# DEBUGSS_DEBUGSS_ARM_CTI_6_CFG_CSCTI_CFG_00073C02D000h register map
Vendor: Texas Instruments
Peripheral module from a debugger description file (folder am62L).
Registers are 32-bit, read-write, reset values left out (the file's numbers can be read two ways) unless marked. A register's access mark holds for its fields unless they carry their own. Offsets are as the file gives them; lines under a group give offsets from that group; [hi:lo] are bit positions; {n}, {i} and the like mark numbered series; 'fields as' and 'values as' point back to an identical list; <NAME> marks a mode.

## DEBUGSS_ARM_CTI_6_CFG_CSCTI_CFG
0x00 DEBUGSS_ARM_CTI_6_CFG_CSCTI_CFG_CTICONTROL — The CTI Control Register enables the CTI. >
  [0] GLBEN — Enables or disables the ECT.
0x10 DEBUGSS_ARM_CTI_6_CFG_CSCTI_CFG_CTIINTACK — The CTI Interrupt Acknowledge Register is write-only. Any bits written as a 1 cause the ctitrigout output signal to be acknowledged. The acknowledgement is cleared when MAPTRIGOUT is deactivated. This register is used when the ctitrigout is used as a sticky output, that is, no hardware acknowledge is supplied, and a software acknowledge is required.
  [7:0] INTACK — Acknowledges the corresponding ctitrigout output. There is one bit of the register for each ctitrigout output. When a 1 is written to a bit in this register, the corresponding ctitrigout is acknowledged and is cleared when MAPTRIGOUT is LOW. Writing a 0 to any of the bits in this register has no effect.
0x14 DEBUGSS_ARM_CTI_6_CFG_CSCTI_CFG_CTIAPPSET — The CTI Application Trigger Set Register is read/write. A write to this register causes a channel event to be raised, corresponding to the bit written to.
  [3:0] APPSET — Setting a bit HIGH generates a channel event for the selected channel. There is one bit of the register for each channel. Read : 0 = application trigger inactive (reset). 1 = application trigger active. Write : 0 = no effect. 1 = generate channel event.
0x18 DEBUGSS_ARM_CTI_6_CFG_CSCTI_CFG_CTIAPPCLEAR — The CTI Interrupt Acknowledge Register is write-only. A write to this register causes a channel event to be cleared, corresponding to the bit written to.
  [3:0] APPCLEAR — Clears corresponding bits in the CTIAPPSET register. There is one bit of the register for each channel. When a 1 is written to a bit in this register, the corresponding application trigger is disabled in the CTIAPPSET register. Writing a 0 to any of the bits in this register has no effect.
0x1C DEBUGSS_ARM_CTI_6_CFG_CSCTI_CFG_CTIAPPPULSE — The CTI Application Pulse Register is write-only. A write to this register causes a channel event pulse, one cticlk period, to be generated, corresponding to the bit written to. The pulse external to the ECT can be extended to multi-cycle by the handshaking interface circuits. This register clears itself immediately, so it can be repeatedly written to without software having to clear it.
  [3:0] APPULSE — Setting a bit HIGH generates a channel event pulse for the selected channel. There is one bit of the register for each channel. When a 1 is written to a bit in this register, a corresponding channel event pulse is generated for one cticlk period. Writing a 0 to any of the bits in this register has no effect.
0x20 DEBUGSS_ARM_CTI_6_CFG_CSCTI_CFG_CTIINEN0 — The CTI Trigger 0 to Channel Enable Register enables the signalling of an event on CTM channels when the core issues a trigger, ctitrigin, to the CTI. Within this register there is one bit for each of the four channels implemented. This register does not affect the application trigger operations.
  [3:0] TRIGINEN — Enables a cross trigger event to the corresponding channel when an ctitrigin is activated. There is one bit of the field for each of the four channels. When a 1 is written to a bit in this register, it enables the ctitrigin signal to generate an event on the respective channel of the CTM. For example, TRIGINEN[0] set to 1 enables ctitrigin onto channel 0. Writing a 0 to any of the bits in this register disables the ctitrigin signal from generating an event on the respective channel of the CTM. Reading this register returns the programmed value.
0x24 DEBUGSS_ARM_CTI_6_CFG_CSCTI_CFG_CTIINEN1 — The CTI Trigger 1 to Channel Enable Register enables the signalling of an event on CTM channels when the core issues a trigger, ctitrigin, to the CTI. Within this register there is one bit for each of the four channels implemented. This register does not affect the application trigger operations.
  fields as DEBUGSS_ARM_CTI_6_CFG_CSCTI_CFG_CTIINEN0
{0x20+4i} DEBUGSS_ARM_CTI_6_CFG_CSCTI_CFG_CTIINEN{i} (i=2..7) — The CTI Trigger to Channel Enable Register 0 enables the signalling of an event on CTM channels when the core issues a trigger, ctitrigin, to the CTI. Within this register there is one bit for each of the four channels implemented. This register does not affect the application trigger operations.
  fields as DEBUGSS_ARM_CTI_6_CFG_CSCTI_CFG_CTIINEN0
0xA0 DEBUGSS_ARM_CTI_6_CFG_CSCTI_CFG_CTIOUTEN0 — The CTI Channel to Trigger 0 Enable Registers define which channels can generate a ctitrigout[0] output. Within this register there is one bit for each of the four channels implemented. This register affects the mapping from application trigger to trigger outputs.
  [3:0] TRIGOUTEN — Changing the value of this bit from a 0 to a 1 enables a channel event for the corresponding channel to generate a ctitrigout[1] output. There is one bit of the field for each of the four channels. When a 1 is written to a bit in this register, the channel input (ctichin) from the CTM is routed to the ctitrigout output. For example, enabling bit 0 enables ctichin[0] to cause a trigger event on the ctitrigout[0] output. When a 0 is written to any of the bits in this register, the channel input (ctichin) from the CTM is not routed to the ctitrigout output. Reading this register returns the programmed value.
{0xA0+4i} DEBUGSS_ARM_CTI_6_CFG_CSCTI_CFG_CTIOUTEN{i} (i=1..7) — The CTI Channel to Trigger {i} Enable Registers define which channels can generate a ctitrigout[{i}] output. Within this register there is one bit for each of the four channels implemented. This register affects the mapping from application trigger to trigger outputs.
  [3:0] TRIGOUTEN — Changing the value of this bit from a 0 to a 1 enables a channel event for the corresponding channel to generate a ctitrigout[{i}] output. There is one bit of the field for each of the four channels. When a 1 is written to a bit in this register, the channel input (ctichin) from the CTM is routed to the ctitrigout output. For example, enabling bit 0 enables ctichin[0] to cause a trigger event on the ctitrigout[{i}] output. When a 0 is written to any of the bits in this register, the channel input (ctichin) from the CTM is not routed to the ctitrigout output. Reading this register returns the programmed value.
0x130 DEBUGSS_ARM_CTI_6_CFG_CSCTI_CFG_CTITRIGINSTATUS ro — The CTI Trigger In Status Register provides the status of the ctitrigin inputs.
  [7:0] TRIGINSTATUS — Shows the status of the ctitrigin inputs. 1 = ctitrigin is active. 0 = ctitrigin is inactive. Because the register provides a view of the raw ctitrigin inputs, the reset value is unknown. There is one bit of the field for each trigger input.
0x134 DEBUGSS_ARM_CTI_6_CFG_CSCTI_CFG_CTITRIGOUTSTATUS ro — The CTI Trigger Out Status Register provides the status of the ctitrigout outputs.
  [7:0] TRIGOUTSTATUS — Shows the status of the ctitrigout outputs. 1 = ctitrigout is active. 0 = ctitrigout is inactive. There is one bit of the field for each trigger output.
0x138 DEBUGSS_ARM_CTI_6_CFG_CSCTI_CFG_CTICHINSTATUS ro — The CTI Channel In Status Register provides the status of the ctichin inputs.
  [3:0] CTICHINSTATUS — Shows the status of the ctichin inputs. 1 = ctichin is active. 0 = ctichin is inactive. Because the register provides a view of the raw ctichin inputs, the reset value is unknown. There is one bit of the field for each channel input.
0x13C DEBUGSS_ARM_CTI_6_CFG_CSCTI_CFG_CTICHOUTSTATUS ro — The CTI Channel Out Status Register provides the status of the CTI ctichout outputs.
  [3:0] CTICHOUTSTATUS — Shows the status of the ctichout outputs. 1 = ctichout is active. 0 = ctichout is inactive. There is one bit of the field for each channel output.
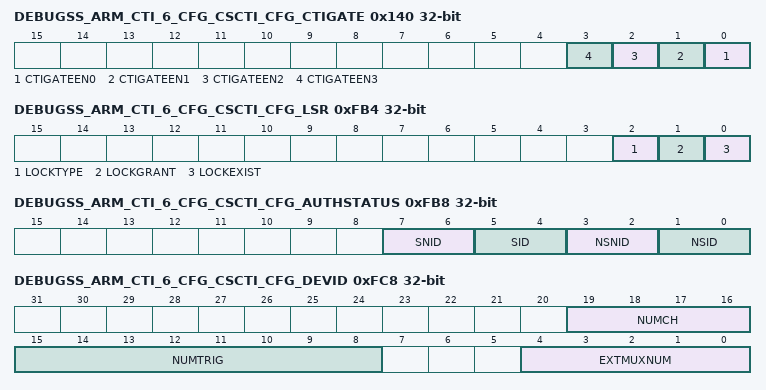
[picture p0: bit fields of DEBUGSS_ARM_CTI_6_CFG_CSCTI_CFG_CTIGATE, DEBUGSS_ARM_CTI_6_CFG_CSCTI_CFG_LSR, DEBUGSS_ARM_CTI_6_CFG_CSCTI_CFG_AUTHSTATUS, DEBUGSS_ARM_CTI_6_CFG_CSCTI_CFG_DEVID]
0x140 DEBUGSS_ARM_CTI_6_CFG_CSCTI_CFG_CTIGATE — The Gate Enable Register prevents the channels from propagating through the CTM to other CTIs. This enables local cross-triggering, for example for causing an interrupt when the ETM trigger occurs. It can be used effectively with CTIAPPSET, CTIAPPCLEAR, and CTIAPPPULSE for asserting trigger outputs by asserting channels, without affecting the rest of the system. On reset, this register is 0xF, and channel propagation is enabled.
  [n] CTIGATEEN{n} (n=0..3) — Enable CTICHOUT{n}. Set to 0 to disable channel propagation.
0x144 DEBUGSS_ARM_CTI_6_CFG_CSCTI_CFG_ASICCTL — Implementation-defined ASIC control, value written to the register is output on asicctl[7 : 0].
  [7:0] ASICCTL — Implementation-defined ASIC control, value written to the register is output on asicctl[7 : 0]. If external multiplexing of trigger signals is implemented then the number of multiplexed signals on each trigger must be reflected within the Device ID Register. This is done within a Verilog define EXTMUXNUM.
0xEDC DEBUGSS_ARM_CTI_6_CFG_CSCTI_CFG_ITCHINACK — This register is a write-only register. It can be used to set the value of the CTCHINACK outputs.
  [3:0] CTCHINACK — Set the value of the CTCHINACK outputs.
0xEE0 DEBUGSS_ARM_CTI_6_CFG_CSCTI_CFG_ITTRIGINACK — This register is a write-only register. It can be used to set the value of the CTTRIGINACK outputs.
  [7:0] CTTRIGINACK — Set the value of the CTTRIGINACK outputs.
0xEE4 DEBUGSS_ARM_CTI_6_CFG_CSCTI_CFG_ITCHOUT — This register is a write-only register. It can be used to set the value of the CTCHOUT outputs.
  [3:0] CTCHOUT — Set the value of the CTCHOUT outputs.
0xEE8 DEBUGSS_ARM_CTI_6_CFG_CSCTI_CFG_ITTRIGOUT — This register is a write-only register. It can be used to set the value of the CTTRIGOUT outputs.
  [7:0] CTTRIGOUT — Set the value of the CTTRIGOUT outputs.
0xEEC DEBUGSS_ARM_CTI_6_CFG_CSCTI_CFG_ITCHOUTACK ro — This register is a read-only register. It can be used to read the values of the CTCHOUTACK inputs.
  [3:0] CTCHOUTACK — Read the values of the CTCHOUTACK inputs.
0xEF0 DEBUGSS_ARM_CTI_6_CFG_CSCTI_CFG_ITTRIGOUTACK ro — This register is a read-only register. It can be used to read the values of the CTTRIGOUTACK inputs.
  [7:0] CTTRIGOUTACK — Read the value of the CTTRIGOUTACK inputs.
0xEF4 DEBUGSS_ARM_CTI_6_CFG_CSCTI_CFG_ITCHIN ro — This register is a read-only register. It can be used to read the values of the CTCHIN inputs.
  [3:0] CTCHIN — Read the value of the CTCHIN inputs.
0xEF8 DEBUGSS_ARM_CTI_6_CFG_CSCTI_CFG_ITTRIGIN ro — This register is a read-only register. It can be used to read the values of the CTTRIGIN inputs.
  [7:0] CTTRIGIN — Read the values of the CTTRIGIN inputs.
0xF00 DEBUGSS_ARM_CTI_6_CFG_CSCTI_CFG_ITCTRL — This register is used to enable topology detection. For more information see the CoreSight Architecture Specification. This register enables the component to switch from a functional mode, the default behavior, to integration mode where the inputs and outputs of the component can be directly controlled for the purpose of integration testing and topology solving. Note : When a device has been in integration mode, it might not function with the original behavior. After performing integration or topology detection, you must reset the system to ensure correct behavior of CoreSight and other connected system components that are affected by the integration or topology detection.
  [0] INTEGRATION_MODE — Allows the component to switch from functional mode to integration mode or back.
0xFA0 DEBUGSS_ARM_CTI_6_CFG_CSCTI_CFG_CLAIMSET — This is used in conjunction with Claim Tag Clear Register, CLAIMCLR. This register forms one half of the Claim Tag value. This location allows individual bits to be set, write, and returns the number of bits that can be set, read.
  [3:0] CLAIMSET — This claim tag bit is implemented
0xFA4 DEBUGSS_ARM_CTI_6_CFG_CSCTI_CFG_CLAIMCLR — This register is used in conjunction with Claim Tag Set Register, CLAIMSET. This register forms one half of the Claim Tag value. This location enables individual bits to be cleared, write, and returns the current Claim Tag value, read.
  [3:0] CLAIMCLR — The value present reflects the current setting of the Claim Tag.
0xFB0 DEBUGSS_ARM_CTI_6_CFG_CSCTI_CFG_LAR — This is used to enable write access to device registers. External accesses from a debugger (paddrdbg31 = 1) are not subject to the Lock Registers. A debugger does not have to unlock the component in order to write and modify the registers in the component.
  [31:0] ACCESS_W — A write of 0xC5ACCE55 enables further write access to this device. A write of any value other than 0xC5ACCE55 will have the affect of removing write access.
0xFB4 DEBUGSS_ARM_CTI_6_CFG_CSCTI_CFG_LSR ro — This indicates the status of the Lock control mechanism. This lock prevents accidental writes by code under debug. When locked, write access is blocked to all registers, except the Lock Access Register. External accesses from a debugger (paddrdbg31 = 1) are not subject to the Lock Registers. This register reads as 0 when read from an external debugger (paddrdbg31 = 1).
  [2] LOCKTYPE — Indicates if the Lock Access Register (0xFB0) is implemented as 8-bit or 32-bit
  [1] LOCKGRANT — Returns the current status of the Lock. This bit reads as 0 when read from an external debugger (paddrdbg31 = 1) since external debugger accesses are not subject to Lock Registers.
  [0] LOCKEXIST — Indicates that a lock control mechanism exists for this device. This bit reads as 0 when read from an external debugger (paddrdbg31 = 1) since external debugger accesses are not subject to Lock Registers.
0xFB8 DEBUGSS_ARM_CTI_6_CFG_CSCTI_CFG_AUTHSTATUS ro — Reports what functionality is currently permitted by the authentication interface.
  [7:6] SNID — Indicates the security level for secure non-invasive debug
  [5:4] SID — Indicates the security level for secure invasive debug
  [3:2] NSNID — Indicates the security level for non-secure non-invasive debug
  [1:0] NSID — Indicates the security level for non-secure invasive debug
0xFC8 DEBUGSS_ARM_CTI_6_CFG_CSCTI_CFG_DEVID ro — This register indicates the capabilities of the CTI.
  [19:16] NUMCH — Number of ECT channels available.
  [15:8] NUMTRIG — Number of ECT triggers available.
  [4:0] EXTMUXNUM — Indicates the number of multiplexing available on Trigger Inputs and Trigger Outputs using asicctl. Default value of 5'b00000 indicating no multiplexing present. Reflects the value of the Verilog define EXTMUXNUM that the user must alter accordingly.
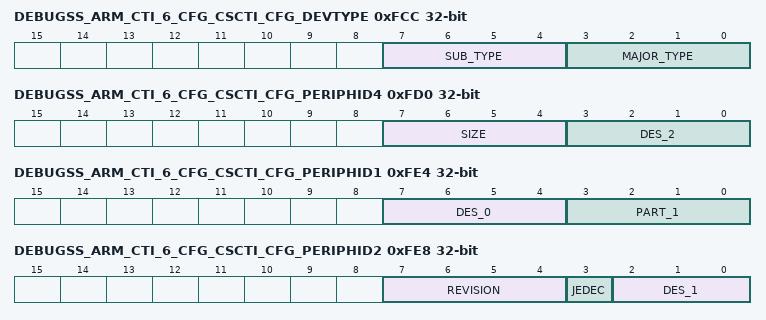
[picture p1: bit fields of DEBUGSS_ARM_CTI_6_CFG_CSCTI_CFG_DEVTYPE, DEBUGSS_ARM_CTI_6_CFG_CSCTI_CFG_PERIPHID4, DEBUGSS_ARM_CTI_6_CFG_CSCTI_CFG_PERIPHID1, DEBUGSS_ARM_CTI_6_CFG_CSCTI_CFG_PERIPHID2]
0xFCC DEBUGSS_ARM_CTI_6_CFG_CSCTI_CFG_DEVTYPE ro — It provides a debugger with information about the component when the Part Number field is not recognized. The debugger can then report this information.
  [7:4] SUB_TYPE — Sub-classification within the major category
  [3:0] MAJOR_TYPE — Major classification grouping for this debug/trace component
0xFD0 DEBUGSS_ARM_CTI_6_CFG_CSCTI_CFG_PERIPHID4 ro — Part of the set of Peripheral Identification registers. Contains part of the designer identity and the memory footprint indicator.
  [7:4] SIZE — This is a 4-bit value that indicates the total contiguous size of the memory window used by this component in powers of 2 from the standard 4KB. If a component only requires the standard 4KB then this should read as 0x0, 4KB only, for 8KB set to 0x1, 16KB == 0x2, 32KB == 0x3, and so on.
  [3:0] DES_2 — JEDEC continuation code indicating the designer of the component (along with the identity code)
0xFE0 DEBUGSS_ARM_CTI_6_CFG_CSCTI_CFG_PERIPHID0 ro — Part of the set of Peripheral Identification registers. Contains part of the designer specific part number.
  [7:0] PART_0 — Bits [7 : 0] of the component's part number. This is selected by the designer of the component.
0xFE4 DEBUGSS_ARM_CTI_6_CFG_CSCTI_CFG_PERIPHID1 ro — Part of the set of Peripheral Identification registers. Contains part of the designer specific part number and part of the designer identity.
  [7:4] DES_0 — Bits 3 : 0 of the JEDEC identity code indicating the designer of the component (along with the continuation code)
  [3:0] PART_1 — Bits [11 : 8] of the component's part number. This is selected by the designer of the component.
0xFE8 DEBUGSS_ARM_CTI_6_CFG_CSCTI_CFG_PERIPHID2 ro — Part of the set of Peripheral Identification registers. Contains part of the designer identity and the product revision.
  [7:4] REVISION — The Revision field is an incremental value starting at 0x0 for the first design of this component. This only increases by 1 for both major and minor revisions and is simply used as a look-up to establish the exact major/minor revision.
  [3] JEDEC — Always set. Indicates that a JEDEC assigned value is used
  [2:0] DES_1 — Bits 6 : 4 of the JEDEC identity code indicating the designer of the component (along with the continuation code)
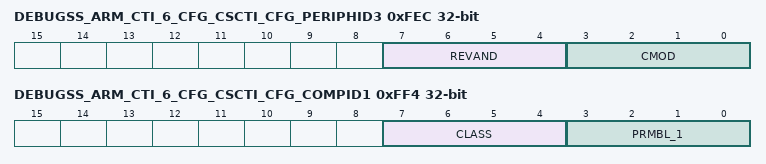
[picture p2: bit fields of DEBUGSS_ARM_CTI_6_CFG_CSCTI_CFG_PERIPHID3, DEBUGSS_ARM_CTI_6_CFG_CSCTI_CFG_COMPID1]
0xFEC DEBUGSS_ARM_CTI_6_CFG_CSCTI_CFG_PERIPHID3 ro — Part of the set of Peripheral Identification registers. Contains the RevAnd and Customer Modified fields.
  [7:4] REVAND — This field indicates minor errata fixes specific to this design, for example metal fixes after implementation. In most cases this field is zero. It is recommended that component designers ensure this field can be changed by a metal fix if required, for example by driving it from registers that reset to zero.
  [3:0] CMOD — Where the component is reusable IP, this value indicates if the customer has modified the behavior of the component. In most cases this field is zero.
0xFF0 DEBUGSS_ARM_CTI_6_CFG_CSCTI_CFG_COMPID0 ro — Reserved Reserved Reserved A component identification register, that indicates that the identification registers are present.
  [7:0] PRMBL_0 — Contains bits [7 : 0] of the component identification
0xFF4 DEBUGSS_ARM_CTI_6_CFG_CSCTI_CFG_COMPID1 ro — A component identification register, that indicates that the identification registers are present. This register also indicates the component class.
  [7:4] CLASS — Class of the component. E.g. ROM table, CoreSight component etc. Constitutes bits [15 : 12] of the component identification.
  [3:0] PRMBL_1 — Contains bits [11 : 8] of the component identification
0xFF8 DEBUGSS_ARM_CTI_6_CFG_CSCTI_CFG_COMPID2 ro — A component identification register, that indicates that the identification registers are present.
  [7:0] PRMBL_2 — Contains bits [23 : 16] of the component identification
0xFFC DEBUGSS_ARM_CTI_6_CFG_CSCTI_CFG_COMPID3 ro — A component identification register, that indicates that the identification registers are present.
  [7:0] PRMBL_3 — Contains bits [31 : 24] of the component identification
